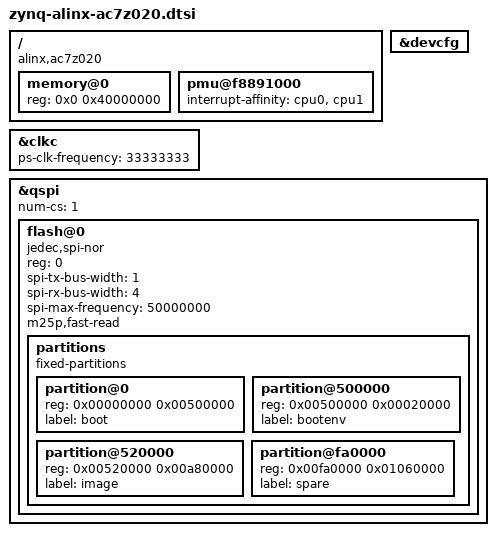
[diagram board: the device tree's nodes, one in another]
// SPDX-License-Identifier: GPL-2.0
/*
 * DTS for ALINX AC7Z020 System on Module
 *
 * Copyright (C) 2026 Pufan Jin <cyan2254650260@gmail.com>
 */

#include "zynq-7000.dtsi"

/ {
	compatible = "alinx,ac7z020", "xlnx,zynq-7000";

	memory@0 {
		device_type = "memory";
		reg = <0x0 0x40000000>;
	};

	pmu@f8891000 {
		interrupt-affinity = <&cpu0>, <&cpu1>;
	};
};

&clkc {
	ps-clk-frequency = <33333333>;
};

&devcfg {
	status = "okay";
};

&qspi {
	bootph-all;
	num-cs = <1>;

	status = "okay";

	flash@0 {
		compatible = "jedec,spi-nor";
		reg = <0>;
		spi-tx-bus-width = <1>;
		spi-rx-bus-width = <4>;
		spi-max-frequency = <50000000>;
		m25p,fast-read;

		partitions {
			compatible = "fixed-partitions";
			#address-cells = <1>;
			#size-cells = <1>;

			partition@0 {
				reg = <0x00000000 0x00500000>;
				label = "boot";
			};

			partition@500000 {
				reg = <0x00500000 0x00020000>;
				label = "bootenv";
			};

			partition@520000 {
				reg = <0x00520000 0x00a80000>;
				label = "image";
			};

			partition@fa0000 {
				reg = <0x00fa0000 0x01060000>;
				label = "spare";
			};
		};
	};
};
